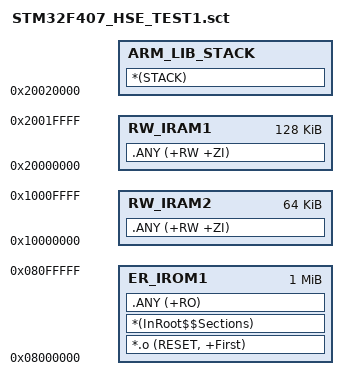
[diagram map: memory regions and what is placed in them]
; *************************************************************
; *** Scatter-Loading Description File generated by uVision ***
; *************************************************************

LR_IROM1 0x08000000 0x00100000  {    ; load region size_region
  ER_IROM1 0x08000000 0x00100000  {  ; load address = execution address
   *.o (RESET, +First)
   *(InRoot$$Sections)
   .ANY (+RO)
  }
  
  ARM_LIB_STACK 0x20020000 -0X400 ; 0x2001FC00
  { *(STACK) }
  
  RW_IRAM1 0x20000000 0x00020000  {  ; RW data
   .ANY (+RW +ZI)
  }
  RW_IRAM2 0x10000000 0x00010000  {
   .ANY (+RW +ZI)
  }
}

